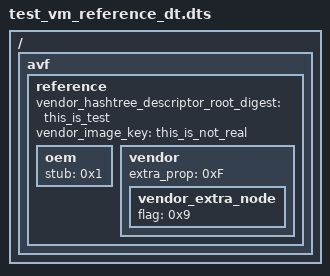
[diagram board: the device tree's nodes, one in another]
/dts-v1/;
/plugin/;

/include/ "test_vm_reference_dt_base.dts"

/ {
	avf {
		reference {
			vendor_hashtree_descriptor_root_digest = "this_is_test";
			vendor_image_key = "this_is_not_real";
			oem {
				stub = <0x1>;
			};
			vendor {
				extra_prop = <0xF>;
				vendor_extra_node {
					flag = <0x9>;
				};
			};
		};
	};
};
